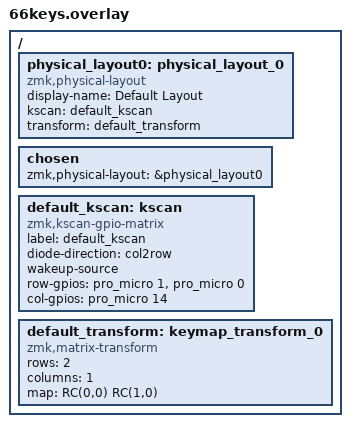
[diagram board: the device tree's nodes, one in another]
/*
 * Copyright (c) 2020 The ZMK Contributors
 *
 * SPDX-License-Identifier: MIT
 */

#include <dt-bindings/zmk/matrix_transform.h>

/ {
    physical_layout0: physical_layout_0 { // First physical layout, use different naming for other layouts
        compatible = "zmk,physical-layout";
        display-name = "Default Layout";
        kscan = <&default_kscan>; // Label of the kscan node, optional if all layouts use the same
        transform = <&default_transform>; // Label of the matrix transform for this layout
    };

    chosen {
        zmk,physical-layout = &physical_layout0;
   };

    default_kscan: kscan {
        compatible = "zmk,kscan-gpio-matrix";
        label = "default_kscan";
        diode-direction = "col2row";
        wakeup-source;

        row-gpios = <&pro_micro 1 (GPIO_ACTIVE_HIGH | GPIO_PULL_DOWN)>,
                    <&pro_micro 0 (GPIO_ACTIVE_HIGH | GPIO_PULL_DOWN)>;

    
        col-gpios = <&pro_micro 14 GPIO_ACTIVE_HIGH>;
    };

    default_transform: keymap_transform_0 {
        compatible = "zmk,matrix-transform";
        rows = <2>;
        columns = <1>;

        map = <
RC(0,0)
RC(1,0)
        >;
    };
};
